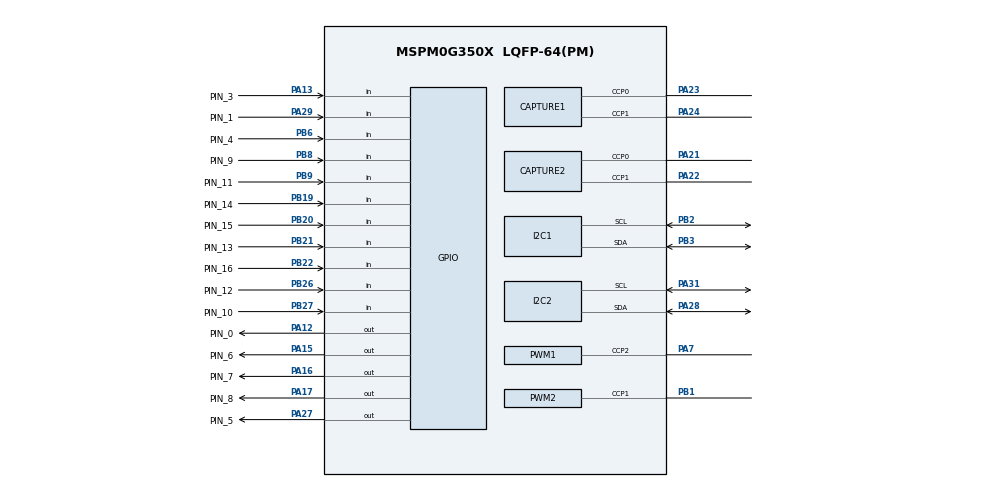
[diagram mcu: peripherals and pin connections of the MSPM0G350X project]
/**
 * @cliArgs --device "MSPM0G350X" --part "Default" --package "LQFP-64(PM)" --product "mspm0_sdk@2.11.00.07"
 * @versions {"tool":"1.26.2+4477"}
 */

/**
 * Import the modules used in this configuration.
 */
const Board    = scripting.addModule("/ti/driverlib/Board");
const CAPTURE  = scripting.addModule("/ti/driverlib/CAPTURE", {}, false);
const CAPTURE1 = CAPTURE.addInstance();
const CAPTURE2 = CAPTURE.addInstance();
const GPIO     = scripting.addModule("/ti/driverlib/GPIO", {}, false);
const GPIO1    = GPIO.addInstance();
const GPIO2    = GPIO.addInstance();
const GPIO3    = GPIO.addInstance();
const GPIO4    = GPIO.addInstance();
const GPIO5    = GPIO.addInstance();
const GPIO6    = GPIO.addInstance();
const GPIO7    = GPIO.addInstance();
const GPIO8    = GPIO.addInstance();
const GPIO9    = GPIO.addInstance();
const GPIO10   = GPIO.addInstance();
const GPIO11   = GPIO.addInstance();
const GPIO12   = GPIO.addInstance();
const GPIO13   = GPIO.addInstance();
const GPIO14   = GPIO.addInstance();
const GPIO15   = GPIO.addInstance();
const GPIO16   = GPIO.addInstance();
const GPIO17   = GPIO.addInstance();
const I2C      = scripting.addModule("/ti/driverlib/I2C", {}, false);
const I2C1     = I2C.addInstance();
const I2C2     = I2C.addInstance();
const PWM      = scripting.addModule("/ti/driverlib/PWM", {}, false);
const PWM1     = PWM.addInstance();
const PWM2     = PWM.addInstance();
const SYSCTL   = scripting.addModule("/ti/driverlib/SYSCTL");
const TIMER    = scripting.addModule("/ti/driverlib/TIMER", {}, false);
const TIMER1   = TIMER.addInstance();

/**
 * Write custom configuration values to the imported modules.
 */
const gate7  = system.clockTree["MFCLKGATE"];
gate7.enable = true;

const gate8  = system.clockTree["MFPCLKGATE"];
gate8.enable = true;

Board.InitPriority2 = "/ti/driverlib/SYSCTL";
Board.InitPriority1 = "/ti/driverlib/QEI";

CAPTURE1.$name                       = "TIMGA";
CAPTURE1.timerClkPrescale            = 32;
CAPTURE1.timerPeriod                 = "65.53 ms";
CAPTURE1.timerStartTimer             = true;
CAPTURE1.captureInputMode            = "multi";
CAPTURE1.ccIndexMulti                = [0,1];
CAPTURE1.multi_countMode             = "DL_TIMER_COUNT_MODE_UP";
CAPTURE1.multi_countRep              = "DL_TIMER_REPEAT_MODE_ENABLED";
CAPTURE1.multi_cvae                  = "DL_TIMER_COUNT_AFTER_EN_ZERO";
CAPTURE1.multi_ch0_captEdgeDetection = "DL_TIMER_CC_CCOND_TRIG_EDGE";
CAPTURE1.multi_ch0_input_filter      = true;
CAPTURE1.multi_ch1_input_filter      = true;
CAPTURE1.interrupts                  = ["CC0_UP","CC1_UP"];
CAPTURE1.peripheral.$assign          = "TIMG0";
CAPTURE1.peripheral.ccp0Pin.$assign  = "PA23";
CAPTURE1.peripheral.ccp1Pin.$assign  = "PA24";
CAPTURE1.ccp0PinConfig.$name         = "ti_driverlib_gpio_GPIOPinGeneric6";
CAPTURE1.ccp1PinConfig.$name         = "ti_driverlib_gpio_GPIOPinGeneric7";

CAPTURE2.$name                       = "TIMGB";
CAPTURE2.timerClkPrescale            = 32;
CAPTURE2.timerPeriod                 = "65.53 ms";
CAPTURE2.timerStartTimer             = true;
CAPTURE2.captureInputMode            = "multi";
CAPTURE2.ccIndexMulti                = [0,1];
CAPTURE2.multi_countMode             = "DL_TIMER_COUNT_MODE_UP";
CAPTURE2.multi_countRep              = "DL_TIMER_REPEAT_MODE_ENABLED";
CAPTURE2.multi_cvae                  = "DL_TIMER_COUNT_AFTER_EN_ZERO";
CAPTURE2.multi_ch0_captEdgeDetection = "DL_TIMER_CC_CCOND_TRIG_EDGE";
CAPTURE2.multi_ch0_input_filter      = true;
CAPTURE2.multi_ch1_input_filter      = true;
CAPTURE2.interrupts                  = ["CC0_UP","CC1_UP"];
CAPTURE2.peripheral.$assign          = "TIMG6";
CAPTURE2.peripheral.ccp0Pin.$assign  = "PA21";
CAPTURE2.peripheral.ccp1Pin.$assign  = "PA22";
CAPTURE2.ccp0PinConfig.$name         = "ti_driverlib_gpio_GPIOPinGeneric8";
CAPTURE2.ccp1PinConfig.$name         = "ti_driverlib_gpio_GPIOPinGeneric9";

GPIO1.$name                         = "BUZZER";
GPIO1.associatedPins[0].$name       = "PIN_0";
GPIO1.associatedPins[0].pin.$assign = "PA12";

GPIO2.$name                                       = "KEY_MODE1";
GPIO2.associatedPins[0].$name                     = "PIN_2";
GPIO2.associatedPins[0].direction                 = "INPUT";
GPIO2.associatedPins[0].ioStructure               = "SD";
GPIO2.associatedPins[0].internalResistor          = "PULL_UP";
GPIO2.associatedPins[0].pin.$assignAllowConflicts = "PB23";

GPIO3.$name                              = "KEY_MODE2";
GPIO3.associatedPins[0].$name            = "PIN_1";
GPIO3.associatedPins[0].direction        = "INPUT";
GPIO3.associatedPins[0].internalResistor = "PULL_UP";
GPIO3.associatedPins[0].pin.$assign      = "PA29";

GPIO4.$name                              = "KEY_MODE3";
GPIO4.associatedPins[0].$name            = "PIN_3";
GPIO4.associatedPins[0].direction        = "INPUT";
GPIO4.associatedPins[0].internalResistor = "PULL_UP";
GPIO4.associatedPins[0].pin.$assign      = "PA13";

GPIO5.$name                              = "KEY_MODE4";
GPIO5.associatedPins[0].$name            = "PIN_4";
GPIO5.associatedPins[0].direction        = "INPUT";
GPIO5.associatedPins[0].internalResistor = "PULL_UP";
GPIO5.associatedPins[0].pin.$assign      = "PB6";

GPIO6.$name                                 = "TB6612_AIN2";
GPIO6.associatedPins[0].$name               = "PIN_6";
GPIO6.associatedPins[0].ioStructure         = "SD";
GPIO6.associatedPins[0].assignedPort        = "PORTA";
GPIO6.associatedPins[0].assignedPortSegment = "Lower";
GPIO6.associatedPins[0].pin.$assign         = "PA15";

GPIO7.$name                          = "TB6612_AIN1";
GPIO7.port                           = "PORTA";
GPIO7.associatedPins[0].$name        = "PIN_5";
GPIO7.associatedPins[0].ioStructure  = "SD";
GPIO7.associatedPins[0].initialValue = "SET";
GPIO7.associatedPins[0].pin.$assign  = "PA27";

GPIO8.$name                         = "TB6612_BIN1";
GPIO8.port                          = "PORTA";
GPIO8.associatedPins[0].$name       = "PIN_7";
GPIO8.associatedPins[0].pin.$assign = "PA16";

GPIO9.$name                          = "TB6612_BIN2";
GPIO9.port                           = "PORTA";
GPIO9.associatedPins[0].$name        = "PIN_8";
GPIO9.associatedPins[0].initialValue = "SET";
GPIO9.associatedPins[0].pin.$assign  = "PA17";

GPIO10.$name                                 = "B08";
GPIO10.associatedPins[0].$name               = "PIN_9";
GPIO10.associatedPins[0].direction           = "INPUT";
GPIO10.associatedPins[0].ioStructure         = "SD";
GPIO10.associatedPins[0].assignedPort        = "PORTB";
GPIO10.associatedPins[0].assignedPortSegment = "Lower";
GPIO10.associatedPins[0].pin.$assign         = "PB8";

GPIO11.$name                                 = "B27";
GPIO11.associatedPins[0].$name               = "PIN_10";
GPIO11.associatedPins[0].ioStructure         = "SD";
GPIO11.associatedPins[0].direction           = "INPUT";
GPIO11.associatedPins[0].assignedPort        = "PORTB";
GPIO11.associatedPins[0].assignedPin         = "27";
GPIO11.associatedPins[0].assignedPortSegment = "Upper";
GPIO11.associatedPins[0].pin.$assign         = "PB27";

GPIO12.$name                         = "B09";
GPIO12.associatedPins[0].$name       = "PIN_11";
GPIO12.associatedPins[0].ioStructure = "SD";
GPIO12.associatedPins[0].direction   = "INPUT";
GPIO12.associatedPins[0].pin.$assign = "PB9";

GPIO13.$name                         = "B26";
GPIO13.associatedPins[0].$name       = "PIN_12";
GPIO13.associatedPins[0].ioStructure = "SD";
GPIO13.associatedPins[0].direction   = "INPUT";
GPIO13.associatedPins[0].pin.$assign = "PB26";

GPIO14.$name                         = "B21";
GPIO14.associatedPins[0].$name       = "PIN_13";
GPIO14.associatedPins[0].ioStructure = "SD";
GPIO14.associatedPins[0].direction   = "INPUT";
GPIO14.associatedPins[0].pin.$assign = "PB21";

GPIO15.$name                         = "B19";
GPIO15.associatedPins[0].$name       = "PIN_14";
GPIO15.associatedPins[0].ioStructure = "SD";
GPIO15.associatedPins[0].direction   = "INPUT";
GPIO15.associatedPins[0].pin.$assign = "PB19";

GPIO16.$name                         = "B20";
GPIO16.associatedPins[0].$name       = "PIN_15";
GPIO16.associatedPins[0].ioStructure = "SD";
GPIO16.associatedPins[0].direction   = "INPUT";
GPIO16.associatedPins[0].pin.$assign = "PB20";

GPIO17.$name                         = "B22";
GPIO17.associatedPins[0].$name       = "PIN_16";
GPIO17.associatedPins[0].direction   = "INPUT";
GPIO17.associatedPins[0].ioStructure = "SD";
GPIO17.associatedPins[0].pin.$assign = "PB22";

I2C1.$name                             = "I2C_oled";
I2C1.basicEnableController             = true;
I2C1.basicEnableTarget                 = true;
I2C1.basicControllerStandardBusSpeed   = "Fast";
I2C1.peripheral.sdaPin.$assign         = "PB3";
I2C1.peripheral.sclPin.$assign         = "PB2";
I2C1.sdaPinConfig.hideOutputInversion  = scripting.forceWrite(false);
I2C1.sdaPinConfig.onlyInternalResistor = scripting.forceWrite(false);
I2C1.sdaPinConfig.passedPeripheralType = scripting.forceWrite("Digital");
I2C1.sdaPinConfig.$name                = "ti_driverlib_gpio_GPIOPinGeneric0";
I2C1.sclPinConfig.hideOutputInversion  = scripting.forceWrite(false);
I2C1.sclPinConfig.onlyInternalResistor = scripting.forceWrite(false);
I2C1.sclPinConfig.passedPeripheralType = scripting.forceWrite("Digital");
I2C1.sclPinConfig.$name                = "ti_driverlib_gpio_GPIOPinGeneric1";

I2C2.$name                             = "MPU6050_I2C";
I2C2.basicEnableController             = true;
I2C2.basicEnableTarget                 = true;
I2C2.basicControllerStandardBusSpeed   = "Fast";
I2C2.peripheral.sdaPin.$assign         = "PA28";
I2C2.peripheral.sclPin.$assign         = "PA31";
I2C2.sdaPinConfig.hideOutputInversion  = scripting.forceWrite(false);
I2C2.sdaPinConfig.onlyInternalResistor = scripting.forceWrite(false);
I2C2.sdaPinConfig.passedPeripheralType = scripting.forceWrite("Digital");
I2C2.sdaPinConfig.$name                = "ti_driverlib_gpio_GPIOPinGeneric2";
I2C2.sclPinConfig.hideOutputInversion  = scripting.forceWrite(false);
I2C2.sclPinConfig.onlyInternalResistor = scripting.forceWrite(false);
I2C2.sclPinConfig.passedPeripheralType = scripting.forceWrite("Digital");
I2C2.sclPinConfig.$name                = "ti_driverlib_gpio_GPIOPinGeneric3";

PWM1.$name                      = "TIMA0_C2";
PWM1.pwmMode                    = "CENTER_ALIGN";
PWM1.dutyArgs                   = "[50,0,0,0]";
PWM1.ccIndex                    = [2];
PWM1.clockPrescale              = 4;
PWM1.timerCount                 = 400;
PWM1.peripheral.$assign         = "TIMA0";
PWM1.peripheral.ccp2Pin.$assign = "PA7";
PWM1.PWM_CHANNEL_2.$name        = "ti_driverlib_pwm_PWMTimerCC0";
PWM1.ccp2PinConfig.$name        = "ti_driverlib_gpio_GPIOPinGeneric5";

PWM2.$name                              = "TIMA1_C1";
PWM2.ccIndex                            = [1];
PWM2.pwmMode                            = "CENTER_ALIGN";
PWM2.clockPrescale                      = 4;
PWM2.timerCount                         = 400;
PWM2.ccp1PinConfig.direction            = scripting.forceWrite("OUTPUT");
PWM2.ccp1PinConfig.hideOutputInversion  = scripting.forceWrite(false);
PWM2.ccp1PinConfig.onlyInternalResistor = scripting.forceWrite(false);
PWM2.ccp1PinConfig.passedPeripheralType = scripting.forceWrite("Digital");
PWM2.ccp1PinConfig.$name                = "ti_driverlib_gpio_GPIOPinGeneric4";
PWM2.peripheral.$assign                 = "TIMA1";
PWM2.peripheral.ccp1Pin.$assign         = "PB1";
PWM2.PWM_CHANNEL_1.$name                = "ti_driverlib_pwm_PWMTimerCC1";

SYSCTL.forceDefaultClkConfig = true;

TIMER1.$name            = "TIMER_0";
TIMER1.timerClkPrescale = 32;
TIMER1.timerMode        = "PERIODIC_UP";
TIMER1.timerStartTimer  = true;
TIMER1.timerPeriod      = "65.536 ms";

/**
 * Pinmux solution for unlocked pins/peripherals. This ensures that minor changes to the automatic solver in a future
 * version of the tool will not impact the pinmux you originally saw.  These lines can be completely deleted in order to
 * re-solve from scratch.
 */
Board.peripheral.$suggestSolution          = "DEBUGSS";
Board.peripheral.swclkPin.$suggestSolution = "PA20";
Board.peripheral.swdioPin.$suggestSolution = "PA19";
I2C1.peripheral.$suggestSolution           = "I2C1";
I2C2.peripheral.$suggestSolution           = "I2C0";
SYSCTL.peripheral.$suggestSolution         = "SYSCTL";
TIMER1.peripheral.$suggestSolution         = "TIMG7";
